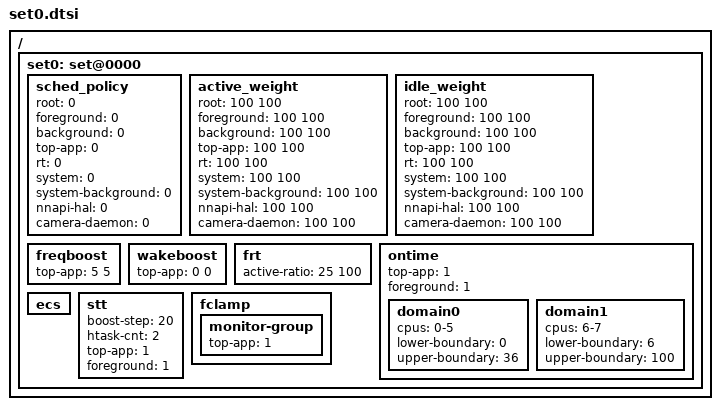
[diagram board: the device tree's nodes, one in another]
/ {
	/* normal mode - default */
	set0: set@0000 {
		sched_policy {
			root = <0>;
			foreground = <0>;
			background = <0>;
			top-app = <0>;
			rt = <0>;
			system = <0>;
			system-background = <0>;
			nnapi-hal = <0>;
			camera-daemon = <0>;
		};

		active_weight {
			root = <100 100>;
			foreground = <100 100>;
			background = <100 100>;
			top-app = <100 100>;
			rt = <100 100>;
			system = <100 100>;
			system-background = <100 100>;
			nnapi-hal = <100 100>;
			camera-daemon = <100 100>;
		};

		idle_weight {
			root = <100 100>;
			foreground = <100 100>;
			background = <100 100>;
			top-app = <100 100>;
			rt = <100 100>;
			system = <100 100>;
			system-background = <100 100>;
			nnapi-hal = <100 100>;
			camera-daemon = <100 100>;
		};

		/* Boosting margin applied to frequency selection */
		freqboost {			/* LIT BIG */
			top-app			= <  5   5>;
		};

		wakeboost {
			top-app = <0 0>;
		};

		frt {	   	     		/* LIT BIG */
			active-ratio		= < 25 100>;
		};

		/* Ontime Migration */
		ontime {
			top-app		= <1>;
			foreground	= <1>;

			domain0 {
				cpus = "0-5";
				lower-boundary = <0>;
				upper-boundary = <36>;
			};
			domain1 {
				cpus = "6-7";
				lower-boundary = <6>;
				upper-boundary = <100>;
			};
		};

		ecs { };

		stt {
			boost-step = <20>;
			htask-cnt = <2>;
			top-app = <1>;
			foreground = <1>;
		};

		fclamp {
			monitor-group {
				top-app         = <1>;
			};
		};
	};
};
